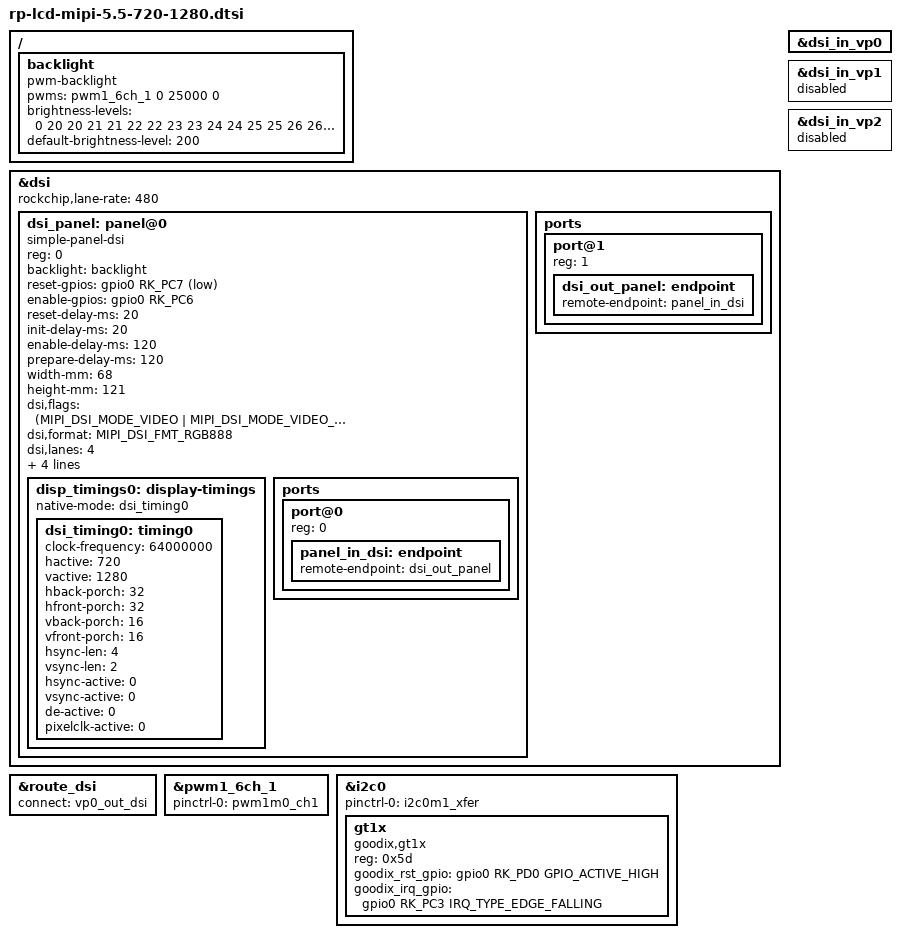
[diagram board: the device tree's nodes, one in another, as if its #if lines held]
/{
    backlight: backlight {
        compatible = "pwm-backlight";
        pwms = <&pwm1_6ch_1 0 25000 0>;
        brightness-levels = <
              0  20  20  21  21  22  22  23
             23  24  24  25  25  26  26  27
             27  28  28  29  29  30  30  31
             31  32  32  33  33  34  34  35
             35  36  36  37  37  38  38  39
             40  41  42  43  44  45  46  47
             48  49  50  51  52  53  54  55
             56  57  58  59  60  61  62  63
             64  65  66  67  68  69  70  71
             72  73  74  75  76  77  78  79
             80  81  82  83  84  85  86  87
             88  89  90  91  92  93  94  95
             96  97  98  99 100 101 102 103
            104 105 106 107 108 109 110 111
            112 113 114 115 116 117 118 119
            120 121 122 123 124 125 126 127
            128 129 130 131 132 133 134 135
            136 137 138 139 140 141 142 143
            144 145 146 147 148 149 150 151
            152 153 154 155 156 157 158 159
            160 161 162 163 164 165 166 167
            168 169 170 171 172 173 174 175
            176 177 178 179 180 181 182 183
            184 185 186 187 188 189 190 191
            192 193 194 195 196 197 198 199
            200 201 202 203 204 205 206 207
            208 209 210 211 212 213 214 215
            216 217 218 219 220 221 222 223
            224 225 226 227 228 229 230 231
            232 233 234 235 236 237 238 239
            240 241 242 243 244 245 246 247
            248 249 250 251 252 253 254 255
        >;
        default-brightness-level = <200>;
    };
};

&dsi {
    status = "okay";
    rockchip,lane-rate = <480>;
    dsi_panel: panel@0 {
        status = "okay";
        compatible = "simple-panel-dsi";
        reg = <0>;
        backlight = <&backlight>;
        
        reset-gpios = <&gpio0 RK_PC7 GPIO_ACTIVE_LOW>;
        enable-gpios = <&gpio0 RK_PC6 GPIO_ACTIVE_HIGH>;
  
	reset-delay-ms = <20>;
        init-delay-ms = <20>;
        enable-delay-ms = <120>;
        prepare-delay-ms = <120>;
 
        width-mm = <68>;
        height-mm = <121>;
        dsi,flags = <(MIPI_DSI_MODE_VIDEO | MIPI_DSI_MODE_VIDEO_BURST |
                  MIPI_DSI_MODE_LPM | MIPI_DSI_MODE_NO_EOT_PACKET)>;
        dsi,format = <MIPI_DSI_FMT_RGB888>;
        dsi,lanes  = <4>;
        panel-init-sequence = [
	    39 00 02 FE 01
            39 00 02 24 C0
            39 00 02 25 53
            39 00 02 26 00
            39 00 02 2B E5
            39 00 02 27 0A
            39 00 02 29 0A
            39 00 02 16 52
            39 00 02 2F 53
            39 00 02 34 5A
            39 00 02 1B 00
            39 00 02 12 0A
            39 00 02 1A 06
            39 00 02 46 4F
            39 00 02 52 A0
            39 00 02 53 00
            39 00 02 54 A0
            39 00 02 55 00
            39 00 02 FE 03
            39 00 02 00 05
            39 00 02 01 16
            39 00 02 02 0B
            39 00 02 03 0F
            39 00 02 04 7D
            39 00 02 05 00
            39 00 02 06 50
            39 00 02 07 05
            39 00 02 08 16
            39 00 02 09 0D
            39 00 02 0A 11
            39 00 02 0B 7D
            39 00 02 0C 00
            39 00 02 0D 50
            39 00 02 0E 07
            39 00 02 0F 08
            39 00 02 10 01
            39 00 02 11 02
            39 00 02 12 00
            39 00 02 13 7D
            39 00 02 14 00
            39 00 02 15 85
            39 00 02 16 08
            39 00 02 17 03
            39 00 02 18 04
            39 00 02 19 05
            39 00 02 1A 06
            39 00 02 1B 00
            39 00 02 1C 7D
            39 00 02 1D 00
            39 00 02 1E 85
            39 00 02 1F 08
            39 00 02 20 00
            39 00 02 21 00
            39 00 02 22 00
            39 00 02 23 00
            39 00 02 24 00
            39 00 02 25 00
            39 00 02 26 00
            39 00 02 27 00
            39 00 02 28 00
            39 00 02 29 00
            39 00 02 2A 07
            39 00 02 2B 08
            39 00 02 2D 01
            39 00 02 2F 02
            39 00 02 30 00
            39 00 02 31 40
            39 00 02 32 05
            39 00 02 33 08
            39 00 02 34 54
            39 00 02 35 7D
            39 00 02 36 00
            39 00 02 37 03
            39 00 02 38 04
            39 00 02 39 05
            39 00 02 3A 06
            39 00 02 3B 00
            39 00 02 3D 40
            39 00 02 3F 05
            39 00 02 40 08
            39 00 02 41 54
            39 00 02 42 7D
            39 00 02 43 00
            39 00 02 44 00
            39 00 02 45 00
            39 00 02 46 00
            39 00 02 47 00
            39 00 02 48 00
            39 00 02 49 00
            39 00 02 4A 00
            39 00 02 4B 00
            39 00 02 4C 00
            39 00 02 4D 00
            39 00 02 4E 00
            39 00 02 4F 00
            39 00 02 50 00
            39 00 02 51 00
            39 00 02 52 00
            39 00 02 53 00
            39 00 02 54 00
            39 00 02 55 00
            39 00 02 56 00
            39 00 02 58 00
            39 00 02 59 00
            39 00 02 5A 00
            39 00 02 5B 00
            39 00 02 5C 00
            39 00 02 5D 00
            39 00 02 5E 00
            39 00 02 5F 00
            39 00 02 60 00
            39 00 02 61 00
            39 00 02 62 00
            39 00 02 63 00
            39 00 02 64 00
            39 00 02 65 00
            39 00 02 66 00
            39 00 02 67 00
            39 00 02 68 00
            39 00 02 69 00
            39 00 02 6A 00
            39 00 02 6B 00
            39 00 02 6C 00
            39 00 02 6D 00
            39 00 02 6E 00
            39 00 02 6F 00
            39 00 02 70 00
            39 00 02 71 00
            39 00 02 72 20
            39 00 02 73 00
            39 00 02 74 08
            39 00 02 75 08
            39 00 02 76 08
            39 00 02 77 08
            39 00 02 78 08
            39 00 02 79 08
            39 00 02 7A 00
            39 00 02 7B 00
            39 00 02 7C 00
            39 00 02 7D 00
            39 00 02 7E BF
            39 00 02 7F 02
            39 00 02 80 06
            39 00 02 81 14
            39 00 02 82 10
            39 00 02 83 16
            39 00 02 84 12
            39 00 02 85 08
            39 00 02 86 3F
            39 00 02 87 3F
            39 00 02 88 3F
            39 00 02 89 3F
            39 00 02 8A 3F
            39 00 02 8B 0C
            39 00 02 8C 0A
            39 00 02 8D 0E
            39 00 02 8E 3F
            39 00 02 8F 3F
            39 00 02 90 00
            39 00 02 91 04
            39 00 02 92 3F
            39 00 02 93 3F
            39 00 02 94 3F
            39 00 02 95 3F
            39 00 02 96 05
            39 00 02 97 01
            39 00 02 98 3F
            39 00 02 99 3F
            39 00 02 9A 0F
            39 00 02 9B 0B
            39 00 02 9C 0D
            39 00 02 9D 3F
            39 00 02 9E 3F
            39 00 02 9F 3F
            39 00 02 A0 3F
            39 00 02 A2 3F
            39 00 02 A3 09
            39 00 02 A4 13
            39 00 02 A5 17
            39 00 02 A6 11
            39 00 02 A7 15
            39 00 02 A9 07
            39 00 02 AA 03
            39 00 02 AB 3F
            39 00 02 AC 3F
            39 00 02 AD 05
            39 00 02 AE 01
            39 00 02 AF 17
            39 00 02 B0 13
            39 00 02 B1 15
            39 00 02 B2 11
            39 00 02 B3 0F
            39 00 02 B4 3F
            39 00 02 B5 3F
            39 00 02 B6 3F
            39 00 02 B7 3F
            39 00 02 B8 3F
            39 00 02 B9 0B
            39 00 02 BA 0D
            39 00 02 BB 09
            39 00 02 BC 3F
            39 00 02 BD 3F
            39 00 02 BE 07
            39 00 02 BF 03
            39 00 02 C0 3F
            39 00 02 C1 3F
            39 00 02 C2 3F
            39 00 02 C3 3F
            39 00 02 C4 02
            39 00 02 C5 06
            39 00 02 C6 3F
            39 00 02 C7 3F
            39 00 02 C8 08
            39 00 02 C9 0C
            39 00 02 CA 0A
            39 00 02 CB 3F
            39 00 02 CC 3F
            39 00 02 CD 3F
            39 00 02 CE 3F
            39 00 02 CF 3F
            39 00 02 D0 0E
            39 00 02 D1 10
            39 00 02 D2 14
            39 00 02 D3 12
            39 00 02 D4 16
            39 00 02 D5 00
            39 00 02 D6 04
            39 00 02 D7 3F
            39 00 02 DC 02
            39 00 02 DE 12
            39 00 02 FE 0E
            39 00 02 01 75
            39 00 02 54 01
            39 00 02 FE 04
            39 00 02 60 00
            39 00 02 61 0C
            39 00 02 62 12
            39 00 02 63 0E
            39 00 02 64 06
            39 00 02 65 12
            39 00 02 66 0E
            39 00 02 67 0B
            39 00 02 68 15
            39 00 02 69 0B
            39 00 02 6A 10
            39 00 02 6B 07
            39 00 02 6C 0F
            39 00 02 6D 12
            39 00 02 6E 0C
            39 00 02 6F 00
            39 00 02 70 00
            39 00 02 6E 0C
            39 00 02 6F 00
            39 00 02 70 00
            39 00 02 71 0C
            39 00 02 72 12
            39 00 02 73 0E
            39 00 02 74 06
            39 00 02 75 12
            39 00 02 76 0E
            39 00 02 77 0B
            39 00 02 78 15
            39 00 02 79 0B
            39 00 02 7A 10
            39 00 02 7B 07
            39 00 02 7C 0F
            39 00 02 7D 12
            39 00 02 7E 0C
            39 00 02 7F 00
            39 00 02 FE 00
            39 00 02 58 AD 
            05 78 01 11
            05 00 01 29
        ];

        panel-exit-sequence = [
            05 00 01 28
            05 00 01 10
        ];

        disp_timings0: display-timings {
            native-mode = <&dsi_timing0>;
            dsi_timing0: timing0 {
		clock-frequency = <64000000>;
                                hactive = <720>;
                                vactive = <1280>;
                                hback-porch = <32>;
                                hfront-porch = <32>;
                                vback-porch = <16>;
                                vfront-porch = <16>;
                                hsync-len = <4>;
                                vsync-len = <2>;
                                hsync-active = <0>;
                                vsync-active = <0>;
                                de-active = <0>;
                                pixelclk-active = <0>;

            };
        };

        ports {
            #address-cells = <1>;
            #size-cells = <0>;

            port@0 {
                reg = <0>;
                panel_in_dsi: endpoint {
                    remote-endpoint = <&dsi_out_panel>;
                };
            };
        };
    };

    ports {
        #address-cells = <1>;
        #size-cells = <0>;

        port@1 {
            reg = <1>;
            dsi_out_panel: endpoint {
                remote-endpoint = <&panel_in_dsi>;
            };
        };
    };

};

#if defined RP_RK3576S || defined DR4_RK3576X || defined PRO_RK3576X

&route_dsi {
    status = "okay";
    connect = <&vp0_out_dsi>;
};

&pwm1_6ch_1 {
    status = "okay";
    pinctrl-0 = <&pwm1m0_ch1>;
};

&dsi_in_vp0 {
    status = "okay";
};

&dsi_in_vp1 {
    status = "disabled";
};

&dsi_in_vp2 {
    status = "disabled";
};


#else  //rk3576

&route_dsi {
    status = "okay";
};

&pwm1_6ch_1 {
    status = "okay";
    pinctrl-0 = <&pwm1m0_ch1>;
};

//default to hdmi
&dsi_in_vp0 {
    status = "disabled";
};

&dsi_in_vp1 {
    status = "okay";
};

&dsi_in_vp2 {
    status = "disabled";
};

&dsi_in_vopl {
    status = "okay";
};
#endif

//TP
&i2c0 {
    status = "okay";
    pinctrl-names = "default";
    pinctrl-0 = <&i2c0m1_xfer>;


gt1x {
    status = "okay";
    compatible = "goodix,gt1x";
    reg = <0x5d>;
    goodix_rst_gpio = <&gpio0 RK_PD0 GPIO_ACTIVE_HIGH>;
    goodix_irq_gpio = <&gpio0 RK_PC3 IRQ_TYPE_EDGE_FALLING>;
    /**
     * goodix,rst-gpio = <>;
     * goodix,irq-gpio = <>;
     *
     * touch panel interrupt and reset pin
     * please refer to ***-lcd-gpio.dtsi
     * that included in main dts.
     */

};
};
